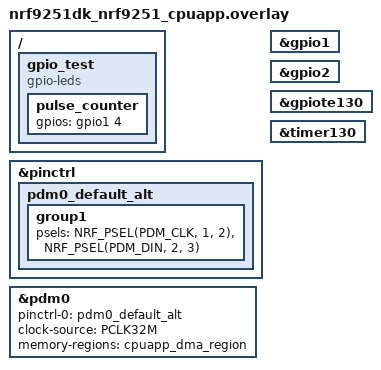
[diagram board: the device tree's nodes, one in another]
/*
 * Copyright (c) 2026 Nordic Semiconductor ASA
 *
 * SPDX-License-Identifier: LicenseRef-Nordic-5-Clause
 */

/* Test requires loopback between P1.02 and P1.04.
 * For best performance, PDM_CLK shall be on 'Clock pin'.
 */

/ {
	gpio_test {
		compatible = "gpio-leds";

		pulse_counter: pulse_counter {
			gpios = <&gpio1 4 GPIO_ACTIVE_HIGH>;
		};
	};
};

&pinctrl {
	pdm0_default_alt: pdm0_default_alt {
		group1 {
			psels = <NRF_PSEL(PDM_CLK, 1, 2)>,
				<NRF_PSEL(PDM_DIN, 2, 3)>;
		};
	};
};

pdm_dev: &pdm0 {
	status = "okay";
	pinctrl-0 = <&pdm0_default_alt>;
	pinctrl-names = "default";
	clock-source = "PCLK32M";
	memory-regions = <&cpuapp_dma_region>;
};

&gpio1 {
	status = "okay";
};

&gpio2 {
	status = "okay";
};

&gpiote130 {
	status = "okay";
};

&timer130 {
	status = "okay";
};
